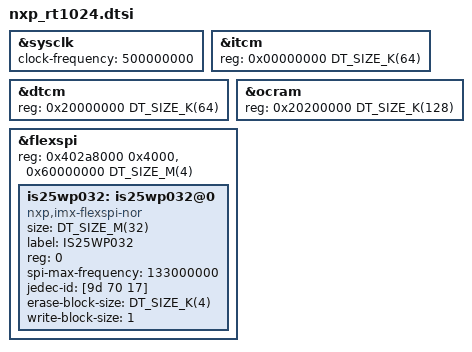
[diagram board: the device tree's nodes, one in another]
/*
 * Copyright (c) 2020, Linaro
 *
 * SPDX-License-Identifier: Apache-2.0
 */

#include <nxp/nxp_rt.dtsi>

&sysclk {
	clock-frequency = <500000000>;
};

/* i.MX rt1024 default FlexRAM partition:
 * ITCM: 64KB
 * DTCM: 64KB
 * OCRAM: 128KB
 */
&itcm {
	reg = <0x00000000 DT_SIZE_K(64)>;
};

&dtcm {
	reg = <0x20000000 DT_SIZE_K(64)>;
};

&ocram {
	reg = <0x20200000 DT_SIZE_K(128)>;
};

&flexspi {
	status = "okay";
	reg = <0x402a8000 0x4000>, <0x60000000 DT_SIZE_M(4)>;
	is25wp032: is25wp032@0 {
		compatible = "nxp,imx-flexspi-nor";
		size = <DT_SIZE_M(32)>;
		label = "IS25WP032";
		reg = <0>;
		spi-max-frequency = <133000000>;
		status = "okay";
		jedec-id = [9d 70 17];
		erase-block-size = <DT_SIZE_K(4)>;
		write-block-size = <1>;
	};
};
